# APM32F411 register map
File version: 1.0
CPU: CM4 r1p0, little endian, no MPU, no FPU, 3 interrupt priority bits
Registers are 32-bit, read-write, reset 0x0 unless marked. A register's access mark holds for its fields unless they carry their own. Offsets are from the block's base; [hi:lo] are bit positions.

## QSPI — Quick Serial peripheral interface
Base 0xA0001000
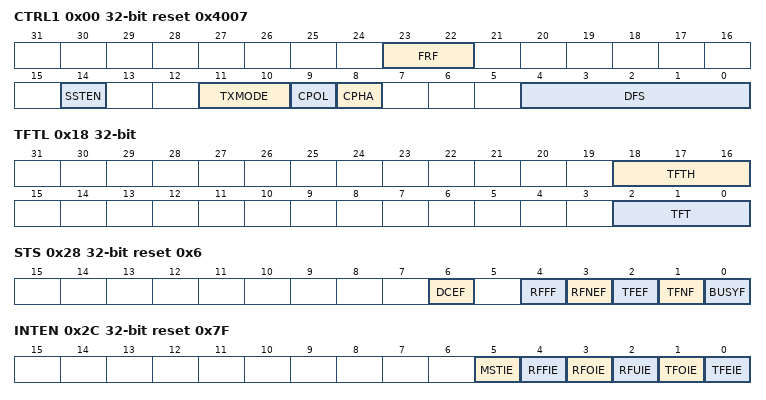
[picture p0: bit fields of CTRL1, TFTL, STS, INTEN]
0x00 CTRL1 reset 0x4007 — Control register 1
  [23:22] FRF, [14] SSTEN, [11:10] TXMODE, [9] CPOL, [8] CPHA, [4:0] DFS
0x04 CTRL2 — Control register 2
  [15:0] NDF
0x08 SSIEN — QSPI Enable register
  [0] EN
0x10 SLAEN — QSPI Slave enable register
  [0] SLAEN
0x14 BR — Baudrate register
  [15:0] CLKDIV
0x18 TFTL — Transmission FIFO threshhold level register
  [18:16] TFTH, [2:0] TFT
0x1C RFTL — Reception FIFO threshhold level register
  [2:0] RFT
0x20 TFL — Transmission FIFO level register
  [2:0] TFL
0x24 RFL — Reception FIFO level register
  [2:0] RFL
0x28 STS reset 0x6 — Status register
  [6] DCEF, [4] RFFF, [3] RFNEF, [2] TFEF, [1] TFNF, [0] BUSYF
0x2C INTEN reset 0x7F — Interrupt enable register
  [5] MSTIE, [4] RFFIE, [3] RFOIE, [2] RFUIE, [1] TFOIE, [0] TFEIE
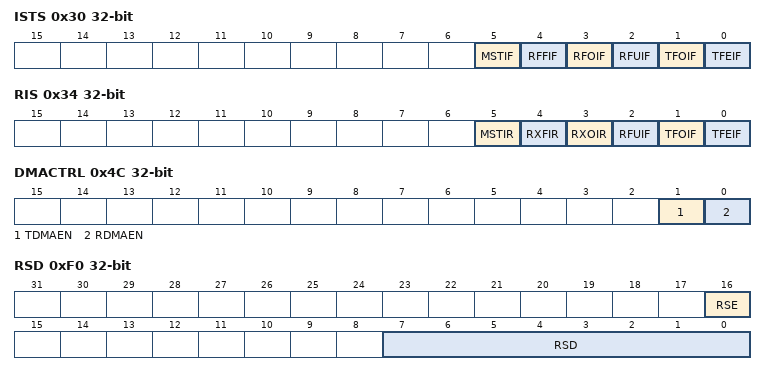
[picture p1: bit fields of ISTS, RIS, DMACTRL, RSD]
0x30 ISTS ro — Interrupt status register
  [5] MSTIF, [4] RFFIF, [3] RFOIF, [2] RFUIF, [1] TFOIF, [0] TFEIF
0x34 RIS ro — Raw interrupt register
  [5] MSTIR, [4] RXFIR, [3] RXOIR, [2] RFUIF, [1] TFOIF, [0] TFEIF
0x38 TFOIC ro — Transmission FIFO overflow interrupt clear register
  [0] TFOIC
0x3C RFOIC ro — Reception FIFO overflow interrupt clear register
  [0] RFOIC
0x40 RFUIC ro — Reception FIFO underflow interrupt clear register
  [0] RFUIC
0x44 MIC ro — Master interrupt clear register
  [0] MIC
0x48 ICF ro — Interrupt clear register
  [0] ICF
0x4C DMACTRL — dma control register
  [1] TDMAEN — Transmit DMA Enable
  [0] RDMAEN — Receive DMA Enable
0x50 DMATDL — dma tx data level register
  [2:0] DMATDL
0x54 DMARDL — dma rx data level register
  [2:0] DMARDL
0x60 DATA
0xF0 RSD — Reception sample register
  [16] RSE, [7:0] RSD
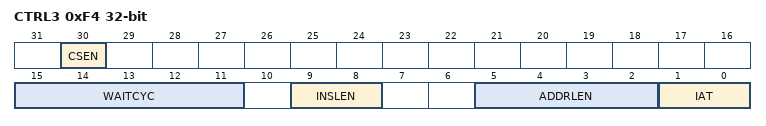
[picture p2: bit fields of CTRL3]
0xF4 CTRL3 — Control register 3
  [30] CSEN, [15:11] WAITCYC, [9:8] INSLEN, [5:2] ADDRLEN, [1:0] IAT
0x200 IOSW — IO switch register
  [0] IOSW — I/O switch

## SPI1 — Serial peripheral interface
Base 0x40013000
Same registers: I2S2ext 0x40003400, SPI2 0x40003800, SPI3 0x40003C00, I2S3ext 0x40004000, SPI4 0x40013400, SPI5 0x40015000
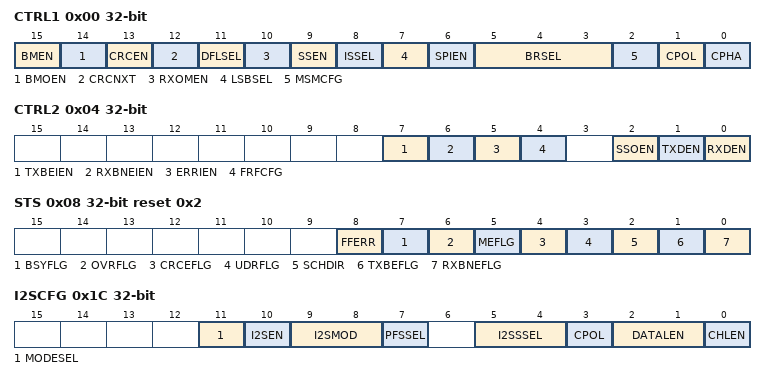
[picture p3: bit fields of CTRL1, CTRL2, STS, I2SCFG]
0x00 CTRL1 — control register 1
  [15] BMEN — Bidirectional data mode enable
  [14] BMOEN — Output enable in bidirectional mode
  [13] CRCEN — Hardware CRC calculation enable
  [12] CRCNXT — CRC transfer next
  [11] DFLSEL — Data frame format
  [10] RXOMEN — Receive only
  [9] SSEN — Software slave management
  [8] ISSEL — Internal slave select
  [7] LSBSEL — Frame format
  [6] SPIEN — SPI enable
  [5:3] BRSEL — Baud rate control
  [2] MSMCFG — Master selection
  [1] CPOL — Clock polarity
  [0] CPHA — Clock phase
0x04 CTRL2 — control register 2
  [7] TXBEIEN — Tx buffer empty interrupt enable
  [6] RXBNEIEN — RX buffer not empty interrupt enable
  [5] ERRIEN — Error interrupt enable
  [4] FRFCFG — Frame Format Configure
  [2] SSOEN — SS output enable
  [1] TXDEN — Tx buffer DMA enable
  [0] RXDEN — Rx buffer DMA enable
0x08 STS access per field reset 0x2 — status register
  [8] FFERR ro — TI frame format error
  [7] BSYFLG ro — Busy flag
  [6] OVRFLG ro — Overrun flag
  [5] MEFLG ro — Mode fault
  [4] CRCEFLG rw — CRC error flag
  [3] UDRFLG ro — Underrun flag
  [2] SCHDIR ro — Channel side
  [1] TXBEFLG ro — Transmit buffer empty
  [0] RXBNEFLG ro — Receive buffer not empty
0x0C DATA
  [15:0] DATA
0x10 CRCPOLY reset 0x7 — CRC polynomial register
  [15:0] CRCPOLY
0x14 RXCRC ro
  [15:0] RXCRC
0x18 TXCRC ro
  [15:0] TXCRC
0x1C I2SCFG — I2S configuration register
  [11] MODESEL — I2S mode selection
  [10] I2SEN — I2S Enable
  [9:8] I2SMOD — I2S configuration mode
  [7] PFSSEL — PCM frame synchronization
  [5:4] I2SSSEL — I2S standard selection
  [3] CPOL — Steady state clock polarity
  [2:1] DATALEN — Data length to be transferred
  [0] CHLEN — Channel length (number of bits per audio channel)
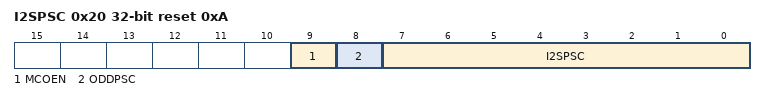
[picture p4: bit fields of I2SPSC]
0x20 I2SPSC reset 0xA — I2S prescaler register
  [9] MCOEN — Master clock output enable
  [8] ODDPSC — Odd factor for the prescaler
  [7:0] I2SPSC — I2S Linear prescaler
